# STM32U073 register map
File version: 1.0
CPU: CM0+ r0p1, little endian, MPU, no FPU, 4 interrupt priority bits
Registers are 32-bit, read-write, reset 0x0 unless marked. A register's access mark holds for its fields unless they carry their own. Offsets are from the block's base; [hi:lo] are bit positions; {n}, {i} and the like mark numbered series.

## LPTIM1 — LPTIM1 address block description
Base 0x40007C00
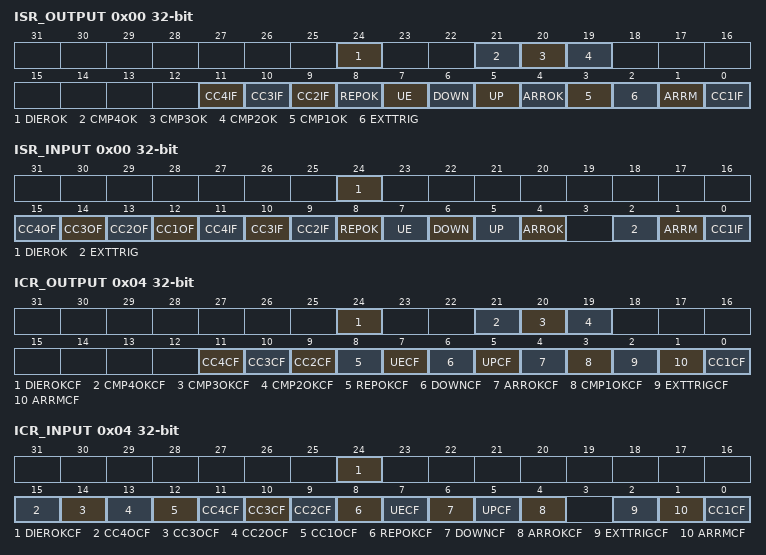
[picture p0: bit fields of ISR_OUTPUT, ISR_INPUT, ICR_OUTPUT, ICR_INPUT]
0x00 ISR_OUTPUT ro — LPTIM1 interrupt and status register [alternate]
  [24] DIEROK — Interrupt enable register update OK DIEROK is set by hardware to inform application that the APB bus write operation to the LPTIM_DIER register has been successfully completed. DIEROK flag can be cleared by writing 1 to the DIEROKCF bit in the LPTIM_ICR register.
  [21] CMP4OK — Compare register 4 update OK CMP4OK is set by hardware to inform application that the APB bus write operation to the LPTIM_CCR4 register has been successfully completed. CMP4OK flag can be cleared by writing 1 to the CMP4OKCF bit in the LPTIM_ICR register. Note: If LPTIM does not implement at least 4 channels this bit is reserved. Refer to Section125.3.
  [20] CMP3OK — Compare register 3 update OK CMP3OK is set by hardware to inform application that the APB bus write operation to the LPTIM_CCR3 register has been successfully completed. CMP3OK flag can be cleared by writing 1 to the CMP3OKCF bit in the LPTIM_ICR register. Note: If LPTIM does not implement at least 3 channels this bit is reserved. Refer to Section125.3.
  [19] CMP2OK — Compare register 2 update OK CMP2OK is set by hardware to inform application that the APB bus write operation to the LPTIM_CCR2 register has been successfully completed. CMP2OK flag can be cleared by writing 1 to the CMP2OKCF bit in the LPTIM_ICR register. Note: If LPTIM does not implement at least 2 channels this bit is reserved. Refer to Section125.3.
  [11] CC4IF — Compare 4 interrupt flag If channel CC4 is configured as output: The CC4IF flag is set by hardware to inform application that LPTIM_CNT register value matches the compare register's value. CC4IF flag can be cleared by writing 1 to the CC4CF bit in the LPTIM_ICR register. Note: If LPTIM does not implement at least 4 channels this bit is reserved. Refer to Section125.3.
  [10] CC3IF — Compare 3 interrupt flag If channel CC3 is configured as output: The CC3IF flag is set by hardware to inform application that LPTIM_CNT register value matches the compare register's value. CC3IF flag can be cleared by writing 1 to the CC3CF bit in the LPTIM_ICR register. Note: If LPTIM does not implement at least 3 channels this bit is reserved. Refer to Section125.3.
  [9] CC2IF — Compare 2 interrupt flag If channel CC2 is configured as output: The CC2IF flag is set by hardware to inform application that LPTIM_CNT register value matches the compare register's value. CC2IF flag can be cleared by writing 1 to the CC2CF bit in the LPTIM_ICR register. Note: If LPTIM does not implement at least 2 channels this bit is reserved. Refer to Section125.3.
  [8] REPOK — Repetition register update OK REPOK is set by hardware to inform application that the APB bus write operation to the LPTIM_RCR register has been successfully completed. REPOK flag can be cleared by writing 1 to the REPOKCF bit in the LPTIM_ICR register.
  [7] UE — LPTIM update event occurred UE is set by hardware to inform application that an update event was generated. The corresponding interrupt or DMA request is generated if enabled. UE flag can be cleared by writing 1 to the UECF bit in the LPTIM_ICR register. The UE flag is automatically cleared by hardware once the LPTIM_ARR register is written by any bus master like CPU or DMA.
  [6] DOWN — Counter direction change up to down In Encoder mode, DOWN bit is set by hardware to inform application that the counter direction has changed from up to down. DOWN flag can be cleared by writing 1 to the DOWNCF bit in the LPTIM_ICR register. Note: If the LPTIM does not support encoder mode feature, this bit is reserved. Refer to Section125.3.
  [5] UP — Counter direction change down to up In Encoder mode, UP bit is set by hardware to inform application that the counter direction has changed from down to up. UP flag can be cleared by writing 1 to the UPCF bit in the LPTIM_ICR register. Note: If the LPTIM does not support encoder mode feature, this bit is reserved. Refer to Section125.3.
  [4] ARROK — Autoreload register update OK ARROK is set by hardware to inform application that the APB bus write operation to the LPTIM_ARR register has been successfully completed. ARROK flag can be cleared by writing 1 to the ARROKCF bit in the LPTIM_ICR register.
  [3] CMP1OK — Compare register 1 update OK CMP1OK is set by hardware to inform application that the APB bus write operation to the LPTIM_CCR1 register has been successfully completed. CMP1OK flag can be cleared by writing 1 to the CMP1OKCF bit in the LPTIM_ICR register.
  [2] EXTTRIG — External trigger edge event EXTTRIG is set by hardware to inform application that a valid edge on the selected external trigger input has occurred. If the trigger is ignored because the timer has already started, then this flag is not set. EXTTRIG flag can be cleared by writing 1 to the EXTTRIGCF bit in the LPTIM_ICR register.
  [1] ARRM — Autoreload match ARRM is set by hardware to inform application that LPTIM_CNT registers value reached the LPTIM_ARR registers value. ARRM flag can be cleared by writing 1 to the ARRMCF bit in the LPTIM_ICR register.
  [0] CC1IF — Compare 1 interrupt flag If channel CC1 is configured as output: The CC1IF flag is set by hardware to inform application that LPTIM_CNT register value matches the compare register's value. CC1IF flag can be cleared by writing 1 to the CC1CF bit in the LPTIM_ICR register.
0x00 ISR_INPUT ro (alternate view of ISR_OUTPUT) — LPTIM1 interrupt and status register [alternate]
  [24] DIEROK — Interrupt enable register update OK DIEROK is set by hardware to inform application that the APB bus write operation to the LPTIM_DIER register has been successfully completed. DIEROK flag can be cleared by writing 1 to the DIEROKCF bit in the LPTIM_ICR register.
  [15] CC4OF — Capture 4 over-capture flag This flag is set by hardware only when the corresponding channel is configured in input capture mode. It is cleared by software by writing 1 to the CC4OCF bit in the LPTIM_ICR register. Note: If LPTIM does not implement at least 4 channels this bit is reserved. Refer to Section125.3.
  [14] CC3OF — Capture 3 over-capture flag This flag is set by hardware only when the corresponding channel is configured in input capture mode. It is cleared by software by writing 1 to the CC3OCF bit in the LPTIM_ICR register. Note: If LPTIM does not implement at least 3 channels this bit is reserved. Refer to Section125.3.
  [13] CC2OF — Capture 2 over-capture flag This flag is set by hardware only when the corresponding channel is configured in input capture mode. It is cleared by software by writing 1 to the CC2OCF bit in the LPTIM_ICR register. Note: If LPTIM does not implement at least 2 channels this bit is reserved. Refer to Section125.3.
  [12] CC1OF — Capture 1 over-capture flag This flag is set by hardware only when the corresponding channel is configured in input capture mode. It is cleared by software by writing 1 to the CC1OCF bit in the LPTIM_ICR register. Note: If LPTIM does not implement at least 1 channel this bit is reserved. Refer to Section125.3.
  [11] CC4IF — Capture 4 interrupt flag If channel CC4 is configured as input: CC4IF is set by hardware to inform application that the current value of the counter is captured in LPTIM_CCR4 register. The corresponding interrupt or DMA request is generated if enabled. The CC4OF flag is set if the CC4IF flag was already high. Note: If LPTIM does not implement at least 4 channels this bit is reserved. Refer to Section125.3.
  [10] CC3IF — Capture 3 interrupt flag If channel CC3 is configured as input: CC3IF is set by hardware to inform application that the current value of the counter is captured in LPTIM_CCR3 register. The corresponding interrupt or DMA request is generated if enabled. The CC3OF flag is set if the CC3IF flag was already high. Note: If LPTIM does not implement at least 3 channels this bit is reserved. Refer to Section125.3.
  [9] CC2IF — Capture 2 interrupt flag If channel CC2 is configured as input: CC2IF is set by hardware to inform application that the current value of the counter is captured in LPTIM_CCR2 register. The corresponding interrupt or DMA request is generated if enabled. The CC2OF flag is set if the CC2IF flag was already high. Note: If LPTIM does not implement at least 2 channels this bit is reserved. Refer to Section125.3.
  [8] REPOK — Repetition register update OK REPOK is set by hardware to inform application that the APB bus write operation to the LPTIM_RCR register has been successfully completed. REPOK flag can be cleared by writing 1 to the REPOKCF bit in the LPTIM_ICR register.
  [7] UE — LPTIM update event occurred UE is set by hardware to inform application that an update event was generated. UE flag can be cleared by writing 1 to the UECF bit in the LPTIM_ICR register.
  [6] DOWN — Counter direction change up to down In Encoder mode, DOWN bit is set by hardware to inform application that the counter direction has changed from up to down. DOWN flag can be cleared by writing 1 to the DOWNCF bit in the LPTIM_ICR register. Note: If the LPTIM does not support encoder mode feature, this bit is reserved. Refer to Section125.3.
  [5] UP — Counter direction change down to up In Encoder mode, UP bit is set by hardware to inform application that the counter direction has changed from down to up. UP flag can be cleared by writing 1 to the UPCF bit in the LPTIM_ICR register. Note: If the LPTIM does not support encoder mode feature, this bit is reserved. Refer to Section125.3.
  [4] ARROK — Autoreload register update OK ARROK is set by hardware to inform application that the APB bus write operation to the LPTIM_ARR register has been successfully completed. ARROK flag can be cleared by writing 1 to the ARROKCF bit in the LPTIM_ICR register.
  [2] EXTTRIG — External trigger edge event EXTTRIG is set by hardware to inform application that a valid edge on the selected external trigger input has occurred. If the trigger is ignored because the timer has already started, then this flag is not set. EXTTRIG flag can be cleared by writing 1 to the EXTTRIGCF bit in the LPTIM_ICR register.
  [1] ARRM — Autoreload match ARRM is set by hardware to inform application that LPTIM_CNT registers value reached the LPTIM_ARR registers value. ARRM flag can be cleared by writing 1 to the ARRMCF bit in the LPTIM_ICR register.
  [0] CC1IF — capture 1 interrupt flag If channel CC1 is configured as input: CC1IF is set by hardware to inform application that the current value of the counter is captured in LPTIM_CCR1 register. The corresponding interrupt or DMA request is generated if enabled. The CC1OF flag is set if the CC1IF flag was already high.
0x04 ICR_OUTPUT wo — LPTIM1 interrupt clear register [alternate]
  [24] DIEROKCF — Interrupt enable register update OK clear flag Writing 1 to this bit clears the DIEROK flag in the LPTIM_ISR register.
  [21] CMP4OKCF — Compare register 4 update OK clear flag Writing 1 to this bit clears the CMP4OK flag in the LPTIM_ISR register. Note: If LPTIM does not implement at least 4 channels this bit is reserved. Refer to Section125.3.
  [20] CMP3OKCF — Compare register 3 update OK clear flag Writing 1 to this bit clears the CMP3OK flag in the LPTIM_ISR register. Note: If LPTIM does not implement at least 3 channels this bit is reserved. Refer to Section125.3.
  [19] CMP2OKCF — Compare register 2 update OK clear flag Writing 1 to this bit clears the CMP2OK flag in the LPTIM_ISR register. Note: If LPTIM does not implement at least 2 channels this bit is reserved. Refer to Section125.3.
  [11] CC4CF — Capture/compare 4 clear flag Writing 1 to this bit clears the CC4IF flag in the LPTIM_ISR register. Note: If LPTIM does not implement at least 4 channels this bit is reserved. Refer to Section125.3.
  [10] CC3CF — Capture/compare 3 clear flag Writing 1 to this bit clears the CC3IF flag in the LPTIM_ISR register. Note: If LPTIM does not implement at least 3 channels this bit is reserved. Refer to Section125.3.
  [9] CC2CF — Capture/compare 2 clear flag Writing 1 to this bit clears the CC2IF flag in the LPTIM_ISR register. Note: If LPTIM does not implement at least 2 channels this bit is reserved. Refer to Section125.3.
  [8] REPOKCF — Repetition register update OK clear flag Writing 1 to this bit clears the REPOK flag in the LPTIM_ISR register.
  [7] UECF — Update event clear flag Writing 1 to this bit clear the UE flag in the LPTIM_ISR register.
  [6] DOWNCF — Direction change to down clear flag Writing 1 to this bit clear the DOWN flag in the LPTIM_ISR register. Note: If the LPTIM does not support encoder mode feature, this bit is reserved. Refer to Section125.3.
  [5] UPCF — Direction change to UP clear flag Writing 1 to this bit clear the UP flag in the LPTIM_ISR register. Note: If the LPTIM does not support encoder mode feature, this bit is reserved. Refer to Section125.3.
  [4] ARROKCF — Autoreload register update OK clear flag Writing 1 to this bit clears the ARROK flag in the LPTIM_ISR register
  [3] CMP1OKCF — Compare register 1 update OK clear flag Writing 1 to this bit clears the CMP1OK flag in the LPTIM_ISR register.
  [2] EXTTRIGCF — External trigger valid edge clear flag Writing 1 to this bit clears the EXTTRIG flag in the LPTIM_ISR register
  [1] ARRMCF — Autoreload match clear flag Writing 1 to this bit clears the ARRM flag in the LPTIM_ISR register
  [0] CC1CF — Capture/compare 1 clear flag Writing 1 to this bit clears the CC1IF flag in the LPTIM_ISR register.
0x04 ICR_INPUT wo (alternate view of ICR_OUTPUT) — LPTIM1 interrupt clear register [alternate]
  [24] DIEROKCF — Interrupt enable register update OK clear flag Writing 1 to this bit clears the DIEROK flag in the LPTIM_ISR register.
  [15] CC4OCF — Capture/compare 4 over-capture clear flag Writing 1 to this bit clears the CC4OF flag in the LPTIM_ISR register. Note: If LPTIM does not implement at least 4 channels this bit is reserved. Refer to Section125.3.
  [14] CC3OCF — Capture/compare 3 over-capture clear flag Writing 1 to this bit clears the CC3OF flag in the LPTIM_ISR register. Note: If LPTIM does not implement at least 3 channels this bit is reserved. Refer to Section125.3.
  [13] CC2OCF — Capture/compare 2 over-capture clear flag Writing 1 to this bit clears the CC2OF flag in the LPTIM_ISR register. Note: If LPTIM does not implement at least 2 channels this bit is reserved. Refer to Section125.3.
  [12] CC1OCF — Capture/compare 1 over-capture clear flag Writing 1 to this bit clears the CC1OF flag in the LPTIM_ISR register. Note: If LPTIM does not implement at least 1 channel this bit is reserved. Refer to Section125.3.
  [11] CC4CF — Capture/compare 4 clear flag Writing 1 to this bit clears the CC4IF flag in the LPTIM_ISR register. Note: If LPTIM does not implement at least 4 channels this bit is reserved. Refer to Section125.3.
  [10] CC3CF — Capture/compare 3 clear flag Writing 1 to this bit clears the CC3IF flag in the LPTIM_ISR register. Note: If LPTIM does not implement at least 3 channels this bit is reserved. Refer to Section125.3.
  [9] CC2CF — Capture/compare 2 clear flag Writing 1 to this bit clears the CC2IF flag in the LPTIM_ISR register. Note: If LPTIM does not implement at least 2 channels this bit is reserved. Refer to Section125.3.
  [8] REPOKCF — Repetition register update OK clear flag Writing 1 to this bit clears the REPOK flag in the LPTIM_ISR register.
  [7] UECF — Update event clear flag Writing 1 to this bit clear the UE flag in the LPTIM_ISR register.
  [6] DOWNCF — Direction change to down clear flag Writing 1 to this bit clear the DOWN flag in the LPTIM_ISR register. Note: If the LPTIM does not support encoder mode feature, this bit is reserved. Refer to Section125.3.
  [5] UPCF — Direction change to UP clear flag Writing 1 to this bit clear the UP flag in the LPTIM_ISR register. Note: If the LPTIM does not support encoder mode feature, this bit is reserved. Refer to Section125.3.
  [4] ARROKCF — Autoreload register update OK clear flag Writing 1 to this bit clears the ARROK flag in the LPTIM_ISR register
  [2] EXTTRIGCF — External trigger valid edge clear flag Writing 1 to this bit clears the EXTTRIG flag in the LPTIM_ISR register
  [1] ARRMCF — Autoreload match clear flag Writing 1 to this bit clears the ARRM flag in the LPTIM_ISR register
  [0] CC1CF — Capture/compare 1 clear flag Writing 1 to this bit clears the CC1IF flag in the LPTIM_ISR register.
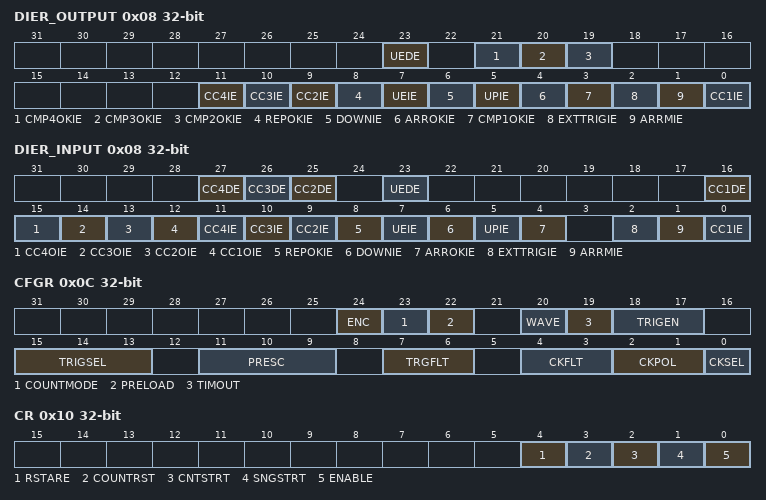
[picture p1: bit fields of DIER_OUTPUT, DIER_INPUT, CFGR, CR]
0x08 DIER_OUTPUT — LPTIM1 interrupt enable register [alternate]
  [23] UEDE — Update event DMA request enable Note: If LPTIM does not implement at least 1 channel this bit is reserved. Refer to Section125.3.
  [21] CMP4OKIE — Compare register 4 update OK interrupt enable Note: If LPTIM does not implement at least 4 channels this bit is reserved. Refer to Section125.3.
  [20] CMP3OKIE — Compare register 3 update OK interrupt enable Note: If LPTIM does not implement at least 3 channels this bit is reserved. Refer to Section125.3.
  [19] CMP2OKIE — Compare register 2 update OK interrupt enable Note: If LPTIM does not implement at least 2 channels this bit is reserved. Refer to Section125.3.
  [11] CC4IE — Capture/compare 4 interrupt enable Note: If LPTIM does not implement at least 4 channels this bit is reserved. Refer to Section125.3.
  [10] CC3IE — Capture/compare 3 interrupt enable Note: If LPTIM does not implement at least 3 channels this bit is reserved. Refer to Section125.3.
  [9] CC2IE — Capture/compare 2 interrupt enable Note: If LPTIM does not implement at least 2 channels this bit is reserved. Refer to Section125.3.
  [8] REPOKIE — Repetition register update OK interrupt Enable
  [7] UEIE — Update event interrupt enable
  [6] DOWNIE — Direction change to down Interrupt Enable Note: If the LPTIM does not support encoder mode feature, this bit is reserved. Refer to Section125.3.
  [5] UPIE — Direction change to UP Interrupt Enable Note: If the LPTIM does not support encoder mode feature, this bit is reserved. Refer to Section125.3.
  [4] ARROKIE — Autoreload register update OK Interrupt Enable
  [3] CMP1OKIE — Compare register 1 update OK interrupt enable
  [2] EXTTRIGIE — External trigger valid edge Interrupt Enable
  [1] ARRMIE — Autoreload match Interrupt Enable
  [0] CC1IE — Capture/compare 1 interrupt enable
0x08 DIER_INPUT (alternate view of DIER_OUTPUT) — LPTIM1 interrupt enable register [alternate]
  [27] CC4DE — Capture/compare 4 DMA request enable Note: If LPTIM does not implement at least 4 channels this bit is reserved. Refer to Section125.3.
  [26] CC3DE — Capture/compare 3 DMA request enable Note: If LPTIM does not implement at least 3 channels this bit is reserved. Refer to Section125.3.
  [25] CC2DE — Capture/compare 2 DMA request enable Note: If LPTIM does not implement at least 2 channels this bit is reserved. Refer to Section125.3.
  [23] UEDE — Update event DMA request enable Note: If LPTIM does not implement at least 1 channel this bit is reserved. Refer to Section125.3.
  [16] CC1DE — Capture/compare 1 DMA request enable Note: If LPTIM does not implement at least 1 channel this bit is reserved. Refer to Section125.3.
  [15] CC4OIE — Capture/compare 4 over-capture interrupt enable Note: If LPTIM does not implement at least 4 channels this bit is reserved. Refer to Section125.3.
  [14] CC3OIE — Capture/compare 3 over-capture interrupt enable Note: If LPTIM does not implement at least 3 channels this bit is reserved. Refer to Section125.3.
  [13] CC2OIE — Capture/compare 2 over-capture interrupt enable Note: If LPTIM does not implement at least 2 channels this bit is reserved. Refer to Section125.3.
  [12] CC1OIE — Capture/compare 1 over-capture interrupt enable Note: If LPTIM does not implement at least 1 channel this bit is reserved. Refer to Section125.3.
  [11] CC4IE — Capture/compare 4 interrupt enable Note: If LPTIM does not implement at least 4 channels this bit is reserved. Refer to Section125.3.
  [10] CC3IE — Capture/compare 3 interrupt enable Note: If LPTIM does not implement at least 3 channels this bit is reserved. Refer to Section125.3.
  [9] CC2IE — Capture/compare 2 interrupt enable Note: If LPTIM does not implement at least 2 channels this bit is reserved. Refer to Section125.3.
  [8] REPOKIE — Repetition register update OK interrupt Enable
  [7] UEIE — Update event interrupt enable
  [6] DOWNIE — Direction change to down Interrupt Enable Note: If the LPTIM does not support encoder mode feature, this bit is reserved. Refer to Section125.3.
  [5] UPIE — Direction change to UP Interrupt Enable Note: If the LPTIM does not support encoder mode feature, this bit is reserved. Refer to Section125.3.
  [4] ARROKIE — Autoreload register update OK Interrupt Enable
  [2] EXTTRIGIE — External trigger valid edge Interrupt Enable
  [1] ARRMIE — Autoreload match Interrupt Enable
  [0] CC1IE — Capture/compare 1 interrupt enable
0x0C CFGR — LPTIM configuration register
  [24] ENC — Encoder mode enable The ENC bit controls the Encoder mode Note: If the LPTIM does not support encoder mode feature, this bit is reserved. Refer to Section125.3.
  [23] COUNTMODE — counter mode enabled The COUNTMODE bit selects which clock source is used by the LPTIM to clock the counter:
  [22] PRELOAD — Registers update mode The PRELOAD bit controls the LPTIM1_ARR, LPTIM1_RCR and the LPTIM1_CCRx registers update modality
  [20] WAVE — Waveform shape The WAVE bit controls the output shape
  [19] TIMOUT — Timeout enable The TIMOUT bit controls the Timeout feature
  [18:17] TRIGEN — Trigger enable and polarity The TRIGEN bits controls whether the LPTIM counter is started by an external trigger or not. If the external trigger option is selected, three configurations are possible for the trigger active edge:
  [15:13] TRIGSEL — Trigger selector The TRIGSEL bits select the trigger source that serves as a trigger event for the LPTIM among the below 8 available sources: See Section125.4.3: LPTIM input and trigger mapping for details.
  [11:9] PRESC — Clock prescaler The PRESC bits configure the prescaler division factor. It can be one among the following division factors:
  [7:6] TRGFLT — Configurable digital filter for trigger The TRGFLT value sets the number of consecutive equal samples that are detected when a level change occurs on an internal trigger before it is considered as a valid level transition. An internal clock source must be present to use this feature
  [4:3] CKFLT — Configurable digital filter for external clock The CKFLT value sets the number of consecutive equal samples that are detected when a level change occurs on an external clock signal before it is considered as a valid level transition. An internal clock source must be present to use this feature
  [2:1] CKPOL — Clock Polarity When the LPTIM is clocked by an external clock source, CKPOL bits is used to configure the active edge or edges used by the counter: If the LPTIM is configured in Encoder mode (ENC bit is set), the encoder sub-mode 1 is active. If the LPTIM is configured in Encoder mode (ENC bit is set), the encoder sub-mode 2 is active. If the LPTIM is configured in Encoder mode (ENC bit is set), the encoder sub-mode 3 is active. Refer to Section125.4.15: Encoder mode for more details about Encoder mode sub-modes.
  [0] CKSEL — Clock selector The CKSEL bit selects which clock source the LPTIM uses:
0x10 CR — LPTIM control register
  [4] RSTARE — Reset after read enable This bit is set and cleared by software. When RSTARE is set to '1', any read access to LPTIM1_CNT register asynchronously resets LPTIM1_CNT register content. This bit can be set only when the LPTIM is enabled.
  [3] COUNTRST — Counter reset This bit is set by software and cleared by hardware. When set to '1' this bit triggers a synchronous reset of the LPTIM1_CNT counter register. Due to the synchronous nature of this reset, it only takes place after a synchronization delay of 3 LPTimer core clock cycles (LPTimer core clock may be different from APB clock). This bit can be set only when the LPTIM is enabled. It is automatically reset by hardware. COUNTRST must never be set to '1' by software before it is already cleared to '0' by hardware. Software must consequently check that COUNTRST bit is already cleared to '0' before attempting to set it to '1'.
  [2] CNTSTRT — Timer start in Continuous mode This bit is set by software and cleared by hardware. In case of software start (TRIGEN[1:0] = 00), setting this bit starts the LPTIM in Continuous mode. If the software start is disabled (TRIGEN[1:0] different than 00), setting this bit starts the timer in Continuous mode as soon as an external trigger is detected. If this bit is set when a single pulse mode counting is ongoing, then the timer does not stop at the next match between the LPTIM1_ARR and LPTIM1_CNT registers and the LPTIM counter keeps counting in Continuous mode. This bit can be set only when the LPTIM is enabled. It is automatically reset by hardware.
  [1] SNGSTRT — LPTIM start in Single mode This bit is set by software and cleared by hardware. In case of software start (TRIGEN[1:0] = 00), setting this bit starts the LPTIM in single pulse mode. If the software start is disabled (TRIGEN[1:0] different than 00), setting this bit starts the LPTIM in single pulse mode as soon as an external trigger is detected. If this bit is set when the LPTIM is in continuous counting mode, then the LPTIM stops at the following match between LPTIM1_ARR and LPTIM1_CNT registers. This bit can only be set when the LPTIM is enabled. It is automatically reset by hardware.
  [0] ENABLE — LPTIM enable The ENABLE bit is set and cleared by software.
0x14 CCR1 — LPTIM compare register 1
  [15:0] CCR1 — Capture/compare 1 value If channel CC1 is configured as output: CCR1 is the value to be loaded in the capture/compare 1 register. Depending on the PRELOAD option, the CCR1 register is immediately updated if the PRELOAD bit is reset and updated at next LPTIM update event if PREOAD bit is reset. The capture/compare register 1 contains the value to be compared to the counter LPTIM1_CNT and signaled on OC1 output. If channel CC1 is configured as input: CCR1 becomes read-only, it contains the counter value transferred by the last input capture 1 event. The LPTIM1_CCR1 register is read-only and cannot be programmed.
0x18 ARR reset 0x1 — LPTIM autoreload register
  [15:0] ARR — Auto reload value ARR is the autoreload value for the LPTIM. This value must be strictly greater than the CCRx[15:0] value.
0x1C CNT ro — LPTIM counter register
  [15:0] CNT — Counter value When the LPTIM is running with an asynchronous clock, reading the LPTIM1_CNT register may return unreliable values. So in this case it is necessary to perform two consecutive read accesses and verify that the two returned values are identical.
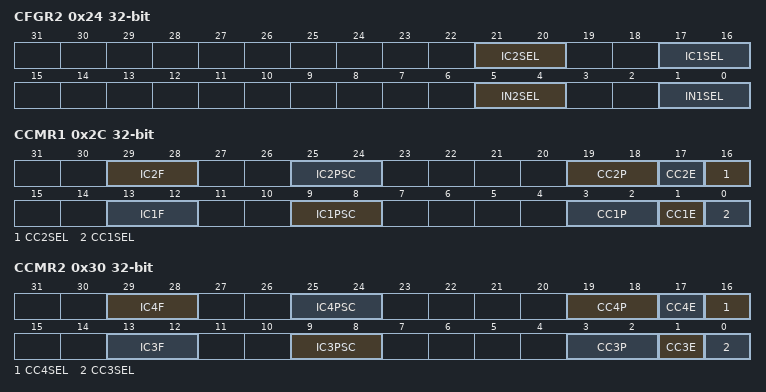
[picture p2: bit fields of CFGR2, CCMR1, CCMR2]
0x24 CFGR2 — LPTIM configuration register 2
  [21:20] IC2SEL — LPTIM input capture 2 selection The IC2SEL bits control the LPTIM Input capture 2 multiplexer, which connects LPTIM Input capture 2 to one of the available inputs. For connection details refer to Section125.4.3: LPTIM input and trigger mapping.
  [17:16] IC1SEL — LPTIM input capture 1 selection The IC1SEL bits control the LPTIM Input capture 1 multiplexer, which connects LPTIM Input capture 1 to one of the available inputs. For connection details refer to Section125.4.3: LPTIM input and trigger mapping.
  [5:4] IN2SEL — LPTIM input 2 selection The IN2SEL bits control the LPTIM input 2 multiplexer, which connects LPTIM input 2 to one of the available inputs. For connection details refer to Section125.4.3: LPTIM input and trigger mapping.
  [1:0] IN1SEL — LPTIM input 1 selection The IN1SEL bits control the LPTIM input 1 multiplexer, which connects LPTIM input 1 to one of the available inputs. For connection details refer to Section125.4.3: LPTIM input and trigger mapping.
0x28 RCR — LPTIM repetition register
  [7:0] REP — Repetition register value REP is the repetition value for the LPTIM.
0x2C CCMR1 — LPTIM capture/compare mode register 1
  [29:28] IC2F — Input capture 2 filter This bitfield defines the number of consecutive equal samples that are detected when a level change occurs on an external input capture signal before it is considered as a valid level transition. An internal clock source must be present to use this feature.
  [25:24] IC2PSC — Input capture 2 prescaler This bitfield defines the ratio of the prescaler acting on the CC2 input (IC2).
  [19:18] CC2P — Capture/compare 2 output polarity. Only bit2 is used to set polarity when output mode is enabled, bit3 is don't care. This field is used to select the IC2 polarity for capture operations.
  [17] CC2E — Capture/compare 2 output enable. This bit determines if a capture of the counter value can actually be done into the input capture/compare register 2 (LPTIM1_CCR2) or not.
  [16] CC2SEL — Capture/compare 2 selection This bitfield defines the direction of the channel, input (capture) or output mode.
  [13:12] IC1F — Input capture 1 filter This bitfield defines the number of consecutive equal samples that are detected when a level change occurs on an external input capture signal before it is considered as a valid level transition. An internal clock source must be present to use this feature.
  [9:8] IC1PSC — Input capture 1 prescaler This bitfield defines the ratio of the prescaler acting on the CC1 input (IC1).
  [3:2] CC1P — Capture/compare 1 output polarity. Only bit2 is used to set polarity when output mode is enabled, bit3 is don't care. This field is used to select the IC1 polarity for capture operations.
  [1] CC1E — Capture/compare 1 output enable. This bit determines if a capture of the counter value can actually be done into the input capture/compare register 1 (LPTIM1_CCR1) or not.
  [0] CC1SEL — Capture/compare 1 selection This bitfield defines the direction of the channel input (capture) or output mode.
0x30 CCMR2 — LPTIM capture/compare mode register 2
  [29:28] IC4F — Input capture 4 filter This bitfield defines the number of consecutive equal samples that should be detected when a level change occurs on an external input capture signal before it is considered as a valid level transition. An internal clock source must be present to use this feature.
  [25:24] IC4PSC — Input capture 4 prescaler This bitfield defines the ratio of the prescaler acting on the CC4 input (IC4).
  [19:18] CC4P — Capture/compare 4 output polarity. Condition: CC4 as output: Only bit2 is used to set polarity when output mode is enabled, bit3 is don't care. Condition: CC4 as input: This field is used to select the IC4 polarity for capture operations.
  [17] CC4E — Capture/compare 4 output enable. Condition: CC4 as output: Condition: CC4 as input: This bit determines if a capture of the counter value can actually be done into the input capture/compare register 4 (LPTIM1_CCR4) or not.
  [16] CC4SEL — Capture/compare 4 selection This bitfield defines the direction of the channel, input (capture) or output mode.
  [13:12] IC3F — Input capture 3 filter This bitfield defines the number of consecutive equal samples that should be detected when a level change occurs on an external input capture signal before it is considered as a valid level transition. An internal clock source must be present to use this feature.
  [9:8] IC3PSC — Input capture 3 prescaler This bitfield defines the ratio of the prescaler acting on the CC3 input (IC3).
  [3:2] CC3P — Capture/compare 3 output polarity. Condition: CC3 as output: Only bit2 is used to set polarity when output mode is enabled, bit3 is don't care. Condition: CC3 as input: This field is used to select the IC3 polarity for capture operations.
  [1] CC3E — Capture/compare 3 output enable. Condition: CC3 as output: Condition: CC3 as input: This bit determines if a capture of the counter value can actually be done into the input capture/compare register 3 (LPTIM1_CCR3) or not.
  [0] CC3SEL — Capture/compare 3 selection This bitfield defines the direction of the channel input (capture) or output mode.
{0x2C+4i} CCR{i} (i=2..4) — LPTIM compare register {i}
  [15:0] CCR{i} — Capture/compare {i} value If channel CC{i} is configured as output: CCR{i} is the value to be loaded in the capture/compare {i} register. Depending on the PRELOAD option, the CCR{i} register is immediately updated if the PRELOAD bit is reset and updated at next LPTIM update event if PREOAD bit is reset. The capture/compare register {i} contains the value to be compared to the counter LPTIM1_CNT and signaled on OC{i} output. If channel CC{i} is configured as input: CCR{i} becomes read-only, it contains the counter value transferred by the last input capture {i} event. The LPTIM1_CCR{i} register is read-only and cannot be programmed.

## LPTIM2 — LPTIM2 address block description
Base 0x40009400
Registers as LPTIM1 (with LPTIM1 read as LPTIM2).

## LPTIM3 — LPTIM3 address block description
Base 0x40009000
Registers as LPTIM1 (with LPTIM1 read as LPTIM3).
